# ATSAMG55J register map
Vendor: Microchip Technology; Series: SAMG55; File version: 0
CPU: CM4 r0p1, little endian, MPU, FPU, 4 interrupt priority bits
Registers are 32-bit, read-write, reset 0x0 unless marked. A register's access mark holds for its fields unless they carry their own. Offsets are from the block's base; [hi:lo] are bit positions; {n}, {i} and the like mark numbered series.

## UHP — USB Host Port
Base 0x4004C000; register names take the prefix UHP_
0x00 UHP_HCREVISION ro — OHCI Revision Number Register
  [7:0] REV — OHCI revision number
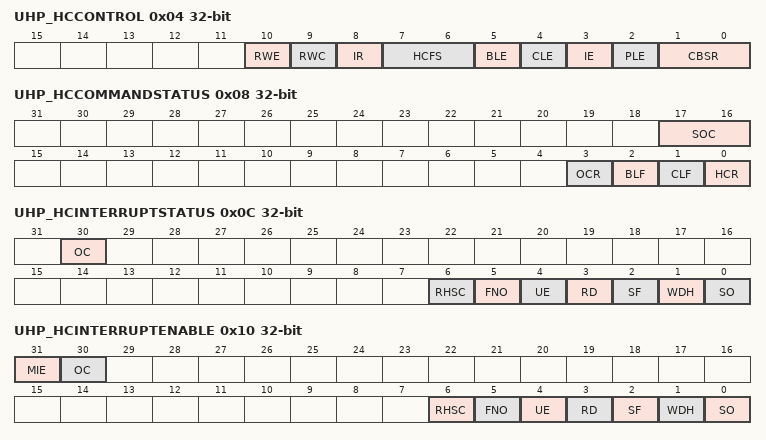
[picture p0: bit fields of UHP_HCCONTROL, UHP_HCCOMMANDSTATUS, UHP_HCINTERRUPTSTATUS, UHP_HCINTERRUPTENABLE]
0x04 UHP_HCCONTROL — HC Operating Mode Register
  [10] RWE — Remote wake-up enable
  [9] RWC — Remote wake-up connected
  [8] IR — Interrupt routing
  [7:6] HCFS — Host controller functional state
  [5] BLE — Bulk list enable
  [4] CLE — Control list enable
  [3] IE — Isochronous enable
  [2] PLE — Periodic list enable
  [1:0] CBSR — Control/bulk service ratio
0x08 UHP_HCCOMMANDSTATUS — HC Command and Status Register
  [17:16] SOC — Scheduling overrun count (read-only)
  [3] OCR — Ownership change request (read/write)
  [2] BLF — Bulk list filled (read/write)
  [1] CLF — Control list filled (read/write)
  [0] HCR — Host controller reset (read/write)
0x0C UHP_HCINTERRUPTSTATUS — HC Interrupt and Status Register
  [30] OC — Ownership change (read-only)
  [6] RHSC — Root hub status change (read/write, write '1' to clear)
  [5] FNO — Frame number overflow (read/write, write '1' to clear)
  [4] UE — Unrecoverable error (read/write, write '1' to clear)
  [3] RD — Resume detected (read/write, write '1' to clear)
  [2] SF — Start of frame (read/write, write '1' to clear)
  [1] WDH — Write done head (read/write, write '1' to clear)
  [0] SO — Scheduling overrun (read/write, write '1' to clear)
0x10 UHP_HCINTERRUPTENABLE — HC Interrupt Enable Register
  [31] MIE — Master interrupt enable (read/write, write '1' to set)
  [30] OC — Ownership change (read-only)
  [6] RHSC — Root hub status change (read/write, write '1' to set)
  [5] FNO — Frame number overflow (read/write, write '1' to set)
  [4] UE — Unrecoverable error (read/write, write '1' to set)
  [3] RD — Resume detected (read/write, write '1' to set)
  [2] SF — Start of frame (read/write, write '1' to set)
  [1] WDH — Write done head (read/write, write '1' to set)
  [0] SO — Scheduling overrun (read/write, write '1' to set)
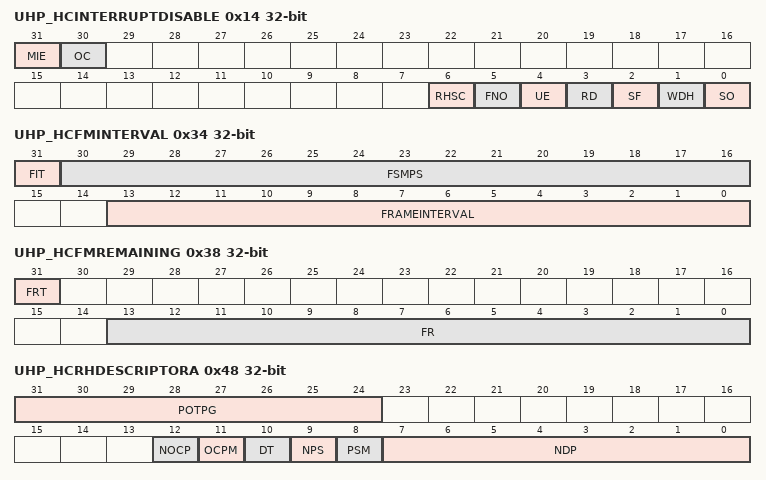
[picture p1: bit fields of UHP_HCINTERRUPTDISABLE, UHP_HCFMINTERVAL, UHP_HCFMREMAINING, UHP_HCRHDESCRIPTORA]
0x14 UHP_HCINTERRUPTDISABLE — HC Interrupt Disable Register
  [31] MIE — Master interrupt enable (read/write)
  [30] OC — Ownership change (read-only)
  [6] RHSC — Root hub status change (read/write)
  [5] FNO — Frame number overflow (read/write)
  [4] UE — Unrecoverable error (read/write)
  [3] RD — Resume detected (read/write)
  [2] SF — Start of frame (read/write)
  [1] WDH — Write done head (read/write)
  [0] SO — Scheduling overrun (read/write)
0x18 UHP_HCHCCA — HC HCCA Address Register
  [31:8] HCCA — Physical address of the beginning of the HCCA
0x1C UHP_HCPERIODCURRENTED ro — HC Current Periodic Register
  [31:4] PCED — Physical address of the current ED on the periodic ED list
0x20 UHP_HCCONTROLHEADED — HC Head Control Register
  [31:4] CHED — Physical address of the head ED on the control ED list
0x24 UHP_HCCONTROLCURRENTED — HC Current Control Register
  [31:4] CCED — Physical address of the current ED on the control ED list
0x28 UHP_HCBULKHEADED — HC Head Bulk Register
  [31:4] BHED — Physical address of the head ED on the bulk ED list
0x2C UHP_HCBULKCURRENTED — HC Current Bulk Register
  [31:4] BCED — Physical address of the current ED on the bulk ED list
0x30 UHP_HCDONEHEAD ro — HC Head Done Register
  [31:4] DH — Physical address of the last TD that has added to the done queue
0x34 UHP_HCFMINTERVAL — HC Frame Interval Register
  [31] FIT — Frame interval toggle
  [30:16] FSMPS — Largest data packet
  [13:0] FRAMEINTERVAL
0x38 UHP_HCFMREMAINING ro — HC Frame Remaining Register
  [31] FRT — Frame remaining toggle
  [13:0] FR — Frame remaining
0x3C UHP_HCFMNUMBER ro — HC Frame Number Register
  [15:0] FN — Frame number
0x40 UHP_HCPERIODICSTART — HC Periodic Start Register
  [13:0] PS — Periodic start
0x44 UHP_HCLSTHRESHOLD — HC Low-Speed Threshold Register
  [13:0] LST — Low-speed threshold
0x48 UHP_HCRHDESCRIPTORA — HC Root Hub A Register
  [31:24] POTPG — Power-on to power-good time (read/write)
  [12] NOCP — No overcurrent protection (read/write)
  [11] OCPM — Overcurrent protection mode (read/write)
  [10] DT — Device type (read-only)
  [9] NPS — No power switching (read/write)
  [8] PSM — Power switching mode (read/write)
  [7:0] NDP — Number of downstream ports (read-only)
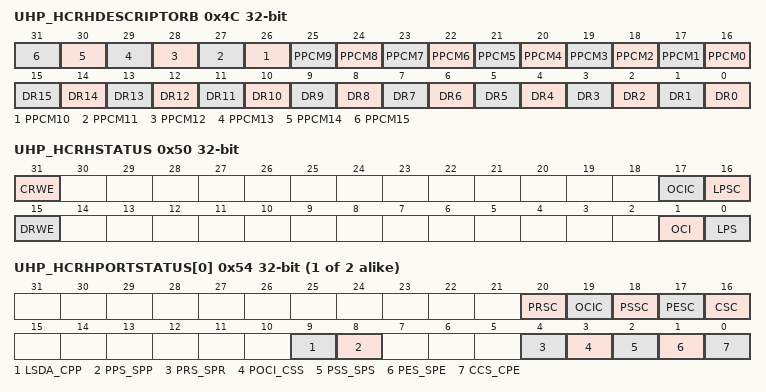
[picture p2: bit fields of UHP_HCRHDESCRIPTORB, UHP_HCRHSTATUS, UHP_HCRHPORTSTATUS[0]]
0x4C UHP_HCRHDESCRIPTORB — HC Root Hub B Register
  [n+16] PPCM{n} (n=0..15), [n] DR{n} (n=0..15)
0x50 UHP_HCRHSTATUS — HC Root Hub Status Register
  [31] CRWE — Clear remote wake-up enable (read/write)
  [17] OCIC — Overcurrent indication change (read/write)
  [16] LPSC — Local power status change (read/write)
  [15] DRWE — Device remote wake-up enable (read/write)
  [1] OCI — Overcurrent indicator (read-only)
  [0] LPS — Local power status (read/write)
{0x54+4i} UHP_HCRHPORTSTATUS[{i}] (i=0..1) — HC Port 1 Status and Control Register 0
  [20] PRSC — Port 1 reset status change (read/write, write '1' to clear)
  [19] OCIC — Port 1 overcurrent indicator change (read/write)
  [18] PSSC — Port 1 suspend status change (read/write, write '1' to clear)
  [17] PESC — Port 1 enable status change (read/write, write '1' to clear)
  [16] CSC — Port 1 connect status change (read/write, write '1' to clear)
  [9] LSDA_CPP
  [8] PPS_SPP
  [4] PRS_SPR
  [3] POCI_CSS
  [2] PSS_SPS
  [1] PES_SPE
  [0] CCS_CPE
